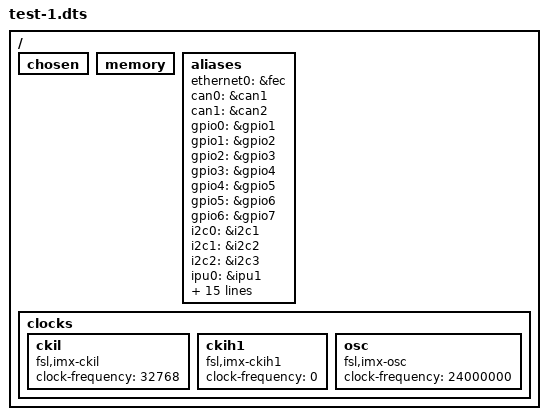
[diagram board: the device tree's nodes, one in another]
/ {
	#address-cells = <1>;
	#size-cells = <1>;
	/*
	 * The decompressor and also some bootloaders rely on a
	 * pre-existing /chosen node to be available to insert the
	 * command line and merge other ATAGS info.
	 * Also for U-Boot there must be a pre-existing /memory node.
	 */
	chosen {};
	memory { device_type = "memory"; };

	aliases {
		ethernet0 = &fec;
		can0 = &can1;
		can1 = &can2;
		gpio0 = &gpio1;
		gpio1 = &gpio2;
		gpio2 = &gpio3;
		gpio3 = &gpio4;
		gpio4 = &gpio5;
		gpio5 = &gpio6;
		gpio6 = &gpio7;
		i2c0 = &i2c1;
		i2c1 = &i2c2;
		i2c2 = &i2c3;
		ipu0 = &ipu1;
		mmc0 = &usdhc1;
		mmc1 = &usdhc2;
		mmc2 = &usdhc3;
		mmc3 = &usdhc4;
		serial0 = &uart1;
		serial1 = &uart2;
		serial2 = &uart3;
		serial3 = &uart4;
		serial4 = &uart5;
		spi0 = &ecspi1;
		spi1 = &ecspi2;
		spi2 = &ecspi3;
		spi3 = &ecspi4;
		usbphy0 = &usbphy1;
		usbphy1 = &usbphy2;
	};

	clocks {
		ckil {
			compatible = "fsl,imx-ckil", "fixed-clock";
			#clock-cells = <0>;
			clock-frequency = <32768>;
		};

		ckih1 {
			compatible = "fsl,imx-ckih1", "fixed-clock";
			#clock-cells = <0>;
			clock-frequency = <0>;
		};

		osc {
			compatible = "fsl,imx-osc", "fixed-clock";
			#clock-cells = <0>;
			clock-frequency = <24000000>;
		};
	};
};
